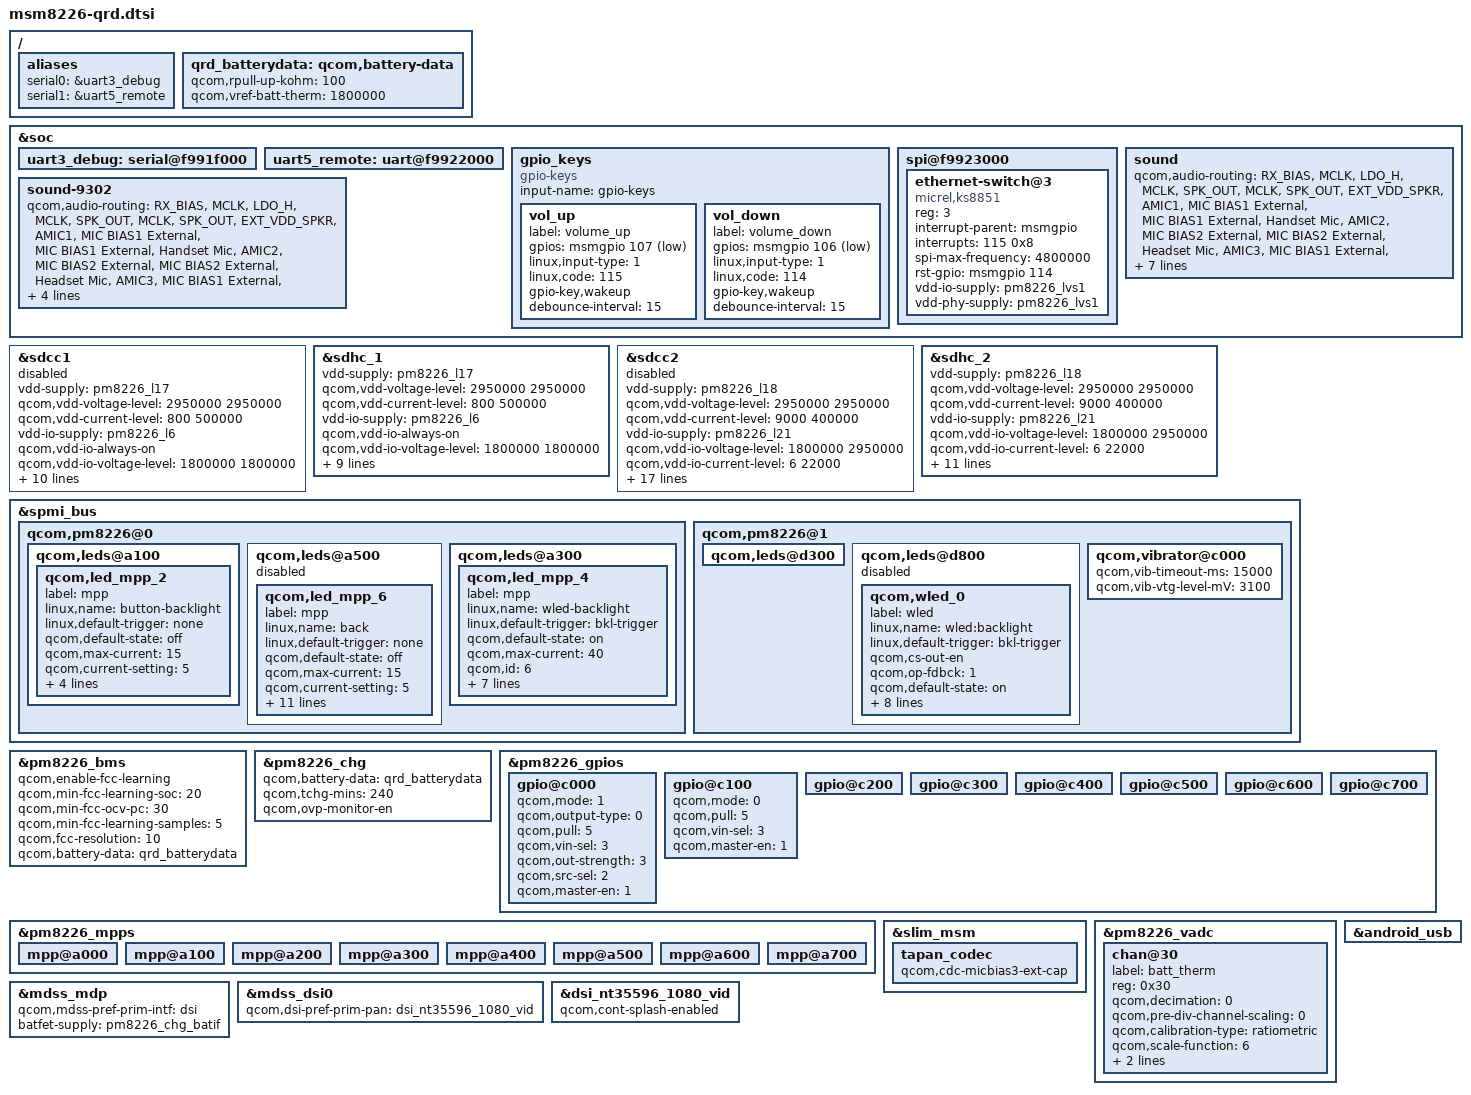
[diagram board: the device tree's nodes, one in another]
/* Copyright (c) 2013, The Linux Foundation. All rights reserved.
 *
 * This program is free software; you can redistribute it and/or modify
 * it under the terms of the GNU General Public License version 2 and
 * only version 2 as published by the Free Software Foundation.
 *
 * This program is distributed in the hope that it will be useful,
 * but WITHOUT ANY WARRANTY; without even the implied warranty of
 * MERCHANTABILITY or FITNESS FOR A PARTICULAR PURPOSE.  See the
 * GNU General Public License for more details.
 */

/include/ "msm8226-camera-sensor-qrd.dtsi"
/*qiang.zhang@Bas Drv add for remote control, uart5 config*/
/ {
    aliases {
        serial0 = &uart3_debug;
        serial1 = &uart5_remote;
    };
};
&soc {
	/*qiang.zhang@Bas Drv add for remote control, uart5 config*/
	uart3_debug: serial@f991f000 {
		status = "ok";
	};
	
	uart5_remote: uart@f9922000 {
		status = "ok";
	};	

	gpio_keys {
		compatible = "gpio-keys";
		input-name = "gpio-keys";
		
		/*Yixue.Ge@ProDrv.BL del for they are no be used at this project*/
		/*camera_focus {
			label = "camera_focus";
			gpios = <&msmgpio 108 0x1>;
			linux,input-type = <1>;
			linux,code = <0x210>;
			gpio-key,wakeup;
			debounce-interval = <15>;
		};

		camera_snapshot {
			label = "camera_snapshot";
			gpios = <&msmgpio 107 0x1>;
			linux,input-type = <1>;
			linux,code = <0x2fe>;
			gpio-key,wakeup;
			debounce-interval = <15>;
		};*/

		vol_up {
			label = "volume_up";
			gpios = <&msmgpio 107 0x1>;
			linux,input-type = <1>;
			linux,code = <115>;
			gpio-key,wakeup;
			debounce-interval = <15>;
		};
		
		vol_down { /*Yixue.Ge@ProDrv.BL add for volume down key*/
			label = "volume_down";
			gpios = <&msmgpio 106 0x1>;
			linux,input-type = <1>;
			linux,code = <114>;
			gpio-key,wakeup;
			debounce-interval = <15>;
		};
	};

	spi@f9923000 {
		ethernet-switch@3 {
			compatible = "micrel,ks8851";
			reg = <3>;
			interrupt-parent = <&msmgpio>;
			interrupts = <115 0x8>;
			spi-max-frequency = <4800000>;
			rst-gpio = <&msmgpio 114 0>;
			vdd-io-supply = <&pm8226_lvs1>;
			vdd-phy-supply = <&pm8226_lvs1>;
		};
	};

	sound {
		qcom,audio-routing =
			"RX_BIAS", "MCLK",
			"LDO_H", "MCLK",
			"SPK_OUT", "MCLK",
			"SPK_OUT", "EXT_VDD_SPKR",
			"AMIC1", "MIC BIAS1 External",
			"MIC BIAS1 External", "Handset Mic",
			"AMIC2", "MIC BIAS2 External",
			"MIC BIAS2 External", "Headset Mic",
			"AMIC3", "MIC BIAS1 External",
			"MIC BIAS1 External", "Analog Mic3",
			"AMIC4", "MIC BIAS3 External",
			"MIC BIAS3 External", "Analog Mic4";

		qcom,cdc-mclk-gpios = <&pm8226_gpios 1 0>;
		qcom,cdc-vdd-spkr-gpios = <&pm8226_gpios 2 0>;
		/*Wensheng.zha@Audio, 2014.03.21, add for 14013 speaker*/
		//qcom,cdc-us-euro-gpios = <&msmgpio 69 0>;
		qcom,cdc-enable-spk-gpios = <&msmgpio 62 0>;
		qcom,cdc-boost-spk-gpios = <&msmgpio 69 0>;		
	};

	sound-9302 {
		qcom,audio-routing =
			"RX_BIAS", "MCLK",
			"LDO_H", "MCLK",
			"SPK_OUT", "MCLK",
			"SPK_OUT", "EXT_VDD_SPKR",
			"AMIC1", "MIC BIAS1 External",
			"MIC BIAS1 External", "Handset Mic",
			"AMIC2", "MIC BIAS2 External",
			"MIC BIAS2 External", "Headset Mic",
			"AMIC3", "MIC BIAS1 External",
			"MIC BIAS1 External", "Handset Mic";

		qcom,cdc-mclk-gpios = <&pm8226_gpios 1 0>;
		qcom,cdc-vdd-spkr-gpios = <&pm8226_gpios 2 0>;
		qcom,cdc-us-euro-gpios = <&msmgpio 69 0>;
	};
};

&sdcc1 {
	vdd-supply = <&pm8226_l17>;
	qcom,vdd-voltage-level = <2950000 2950000>;
	qcom,vdd-current-level = <800 500000>;

	vdd-io-supply = <&pm8226_l6>;
	qcom,vdd-io-always-on;
	qcom,vdd-io-voltage-level = <1800000 1800000>;
	qcom,vdd-io-current-level = <250 154000>;

	qcom,pad-pull-on = <0x0 0x3 0x3>; /* no-pull, pull-up, pull-up */
	qcom,pad-pull-off = <0x0 0x3 0x3>; /* no-pull, pull-up, pull-up */
	qcom,pad-drv-on = <0x4 0x4 0x4>; /* 10mA, 10mA, 10mA */
	qcom,pad-drv-off = <0x0 0x0 0x0>; /* 2mA, 2mA, 2mA */

	qcom,clk-rates = <400000 25000000 50000000 100000000 200000000>;
	qcom,sup-voltages = <2950 2950>;

	qcom,bus-speed-mode = "HS200_1p8v", "DDR_1p8v";
	qcom,nonremovable;

	status = "disabled";
};

&sdhc_1 {
	vdd-supply = <&pm8226_l17>;
	qcom,vdd-voltage-level = <2950000 2950000>;
	qcom,vdd-current-level = <800 500000>;

	vdd-io-supply = <&pm8226_l6>;
	qcom,vdd-io-always-on;
	qcom,vdd-io-voltage-level = <1800000 1800000>;
	qcom,vdd-io-current-level = <250 154000>;

	qcom,pad-pull-on = <0x0 0x3 0x3>; /* no-pull, pull-up, pull-up */
	qcom,pad-pull-off = <0x0 0x3 0x3>; /* no-pull, pull-up, pull-up */
	qcom,pad-drv-on = <0x4 0x4 0x4>; /* 10mA, 10mA, 10mA */
	qcom,pad-drv-off = <0x0 0x0 0x0>; /* 2mA, 2mA, 2mA */

	qcom,clk-rates = <400000 25000000 50000000 100000000 200000000>;
	qcom,bus-speed-mode = "HS200_1p8v", "DDR_1p8v";
	qcom,nonremovable;

	status = "ok";
};

&sdcc2 {
	vdd-supply = <&pm8226_l18>;
	qcom,vdd-voltage-level = <2950000 2950000>;
	qcom,vdd-current-level = <9000 400000>;

	vdd-io-supply = <&pm8226_l21>;
	qcom,vdd-io-voltage-level = <1800000 2950000>;
	qcom,vdd-io-current-level = <6 22000>;

	qcom,pad-pull-on = <0x0 0x3 0x3>; /* no-pull, pull-up, pull-up */
	qcom,pad-pull-off = <0x0 0x3 0x3>; /* no-pull, pull-up, pull-up */
	qcom,pad-drv-on = <0x4 0x4 0x4>; /* 10mA, 10mA, 10mA */
	qcom,pad-drv-off = <0x0 0x0 0x0>; /* 2mA, 2mA, 2mA */

	qcom,clk-rates = <400000 25000000 50000000 100000000 200000000>;
	qcom,sup-voltages = <2950 2950>;

	qcom,xpc;
	qcom,bus-speed-mode = "SDR12", "SDR25", "SDR50", "DDR50", "SDR104";
	qcom,current-limit = <400>;

	#address-cells = <0>;
	interrupt-parent = <&sdcc2>;
	interrupts = <0 1 2>;
	#interrupt-cells = <1>;
	interrupt-map-mask = <0xffffffff>;
	interrupt-map = <0 &intc 0 125 0
			1 &intc 0 220 0
			2 &msmgpio 38 0x3>;
	interrupt-names = "core_irq", "bam_irq", "status_irq";
	cd-gpios = <&msmgpio 38 0x1>;

	status = "disabled";
};

&sdhc_2 {
	vdd-supply = <&pm8226_l18>;
	qcom,vdd-voltage-level = <2950000 2950000>;
	qcom,vdd-current-level = <9000 400000>;

	vdd-io-supply = <&pm8226_l21>;
	qcom,vdd-io-voltage-level = <1800000 2950000>;
	qcom,vdd-io-current-level = <6 22000>;

	qcom,pad-pull-on = <0x0 0x3 0x3>; /* no-pull, pull-up, pull-up */
	qcom,pad-pull-off = <0x0 0x3 0x3>; /* no-pull, pull-up, pull-up */
	qcom,pad-drv-on = <0x4 0x4 0x4>; /* 10mA, 10mA, 10mA */
	qcom,pad-drv-off = <0x0 0x0 0x0>; /* 2mA, 2mA, 2mA */

	qcom,clk-rates = <400000 25000000 50000000>;

	#address-cells = <0>;
	interrupt-parent = <&sdhc_2>;
	interrupts = <0 1 2>;
	#interrupt-cells = <1>;
	interrupt-map-mask = <0xffffffff>;
	interrupt-map = <0 &intc 0 125 0
			1 &intc 0 221 0
			2 &msmgpio 38 0x3>;
	interrupt-names = "hc_irq", "pwr_irq", "status_irq";
	cd-gpios = <&msmgpio 38 0x1>;

	status = "ok";
};

&spmi_bus {
	qcom,pm8226@0 {
		qcom,leds@a100 {
			status = "okay";
			qcom,led_mpp_2 {
				label = "mpp";
				linux,name = "button-backlight";
				linux,default-trigger = "none";
				qcom,default-state = "off";
				qcom,max-current = <15>;
				qcom,current-setting = <5>;
				qcom,id = <6>;
				qcom,mode = "manual";
				qcom,source-sel = <1>;
				qcom,mode-ctrl = <0x60>;
			};
		};



		qcom,leds@a500 {
			status = "disable";
			qcom,led_mpp_6 {
				label = "mpp";
				linux,name = "back";
                //#ifndef VENDOR_EDIT
                //Lycan.Wang@Prd.BasicDrv, 2014-02-26 Remove for no linux trigger
                //linux,default-trigger = "battery-charging";
                //#else
                linux,default-trigger = "none";
                //#endif /* VENDOR_EDIT */
				qcom,default-state = "off";
				qcom,max-current = <15>;
				qcom,current-setting = <5>;
				qcom,id = <6>;
				qcom,mode = "pwm";
				qcom,pwm-us = <1000>;
				qcom,mode-ctrl = <0x60>;
				qcom,source-sel = <10>;
				qcom,pwm-channel = <5>;
				qcom,start-idx = <1>;
                //#ifndef VENDOR_EDIT
                //Lycan.Wang@Prd.BasicDrv, 2014-02-28 Modify for breath-led blink para
                //qcom,ramp-step-ms = <120>;
                //qcom,duty-pcts = [00 00 00 00 00
                //		  00 00 00 00 00
                //		  50 00 00 00 00
                //		  00 00 00 00 00
                //		  00];
                //#else /* VENDOR_EDIT */
                qcom,ramp-step-ms = <100>;
				qcom,duty-pcts = [10 15 20 25 30 35 40 45 50
                          55 60 65 70 75 80 80 80 80 80
                          80 80 75 70 65 60 55 50 45 40
                          35 30 25 20 15 10 00 00 00 00
                          00 00 00 00 00 00 00 00 00 00
                          00 00 00 00 00 00];
                //#endif /* VENDOR_EDIT */
				qcom,use-blink;
			};
		};
	qcom,leds@a300 {
			status = "okay";
			qcom,led_mpp_4 {
				label = "mpp";
				linux,name = "wled-backlight";
				linux,default-trigger = "bkl-trigger";
				qcom,default-state = "on";
				qcom,max-current = <40>;
				qcom,id = <6>;
				qcom,source-sel = <8>;
				qcom,mode-ctrl = <0x10>;
				qcom,pwm-channel = <0>;
				qcom,pwm-us = <31>;
				qcom,vin-ctrl = <0x03>;
				qcom,mode = "pwm";
				qcom,min-brightness = <9>;
			};
		};
		
	};

	qcom,pm8226@1 {	
		qcom,leds@d300 {
				status = "okay"; //zhengrong.zhang@camera.drv modify for led from tong.han modify
		};

		qcom,leds@d800 {
//caven.han@basic.drv added avoid loading devices doesn't exist for 13095
//#ifdef VENDOR_EDIT
				status = "disable";
//#else
//				status = "okay";
//#endif
			qcom,wled_0 {
				label = "wled";
				linux,name = "wled:backlight";
				linux,default-trigger = "bkl-trigger";
				qcom,cs-out-en;
				qcom,op-fdbck = <1>;
				qcom,default-state = "on";
				qcom,max-current = <20>;
				qcom,ctrl-delay-us = <0>;
				qcom,boost-curr-lim = <3>;
				qcom,cp-sel = <0>;
				qcom,switch-freq = <11>;
				qcom,ovp-val = <0>;
				qcom,num-strings = <1>;
				qcom,id = <0>;
			};
		};
		
		qcom,vibrator@c000 {
			status = "okay";
			qcom,vib-timeout-ms = <15000>;
			qcom,vib-vtg-level-mV = <3100>;
		};

	};
};

/ {
	qrd_batterydata: qcom,battery-data {
		qcom,rpull-up-kohm = <100>;
		qcom,vref-batt-therm = <1800000>;

		/include/ "batterydata-qrd-4v35-2000mah.dtsi"
	};
};

&pm8226_bms {
	status = "okay";
	qcom,enable-fcc-learning;
	qcom,min-fcc-learning-soc = <20>;
	qcom,min-fcc-ocv-pc = <30>;
	qcom,min-fcc-learning-samples = <5>;
	qcom,fcc-resolution = <10>;
	qcom,battery-data = <&qrd_batterydata>;
};

&pm8226_chg {
	status = "okay";
	qcom,battery-data = <&qrd_batterydata>;
	qcom,tchg-mins = <240>;
	qcom,ovp-monitor-en;
};

&pm8226_gpios {
	gpio@c000 { /* GPIO 1 */
		/* XO_PMIC_CDC_MCLK enable for tapan codec */
		qcom,mode = <1>;		/* Digital output */
		qcom,output-type = <0>;	/* CMOS logic */
		qcom,pull = <5>;		/* QPNP_PIN_PULL_NO*/
		qcom,vin-sel = <3>;		/* QPNP_PIN_VIN3 */
		qcom,out-strength = <3>;/* QPNP_PIN_OUT_STRENGTH_HIGH */
		qcom,src-sel = <2>;		/* QPNP_PIN_SEL_FUNC_1 */
		qcom,master-en = <1>;	/* Enable GPIO */
	};

	gpio@c100 { /* GPIO 2 */
		qcom,mode = <0>;
		qcom,pull = <5>;
		qcom,vin-sel = <3>;
		qcom,master-en = <1>;
	};

	gpio@c200 { /* GPIO 3 */
	};

	gpio@c300 { /* GPIO 4 */
	};

	gpio@c400 { /* GPIO 5 */
	};

	gpio@c500 { /* GPIO 6 */
	};

	gpio@c600 { /* GPIO 7 */
	};

	gpio@c700 { /* GPIO 8 */
	};
};

&pm8226_mpps {
	mpp@a000 { /* MPP 1 */
	};

	mpp@a100 { /* MPP 2 */
	};

	mpp@a200 { /* MPP 3 */
	};

	mpp@a300 { /* MPP 4 */
	};

	mpp@a400 { /* MPP 5 */
	};

	mpp@a500 { /* MPP 6 */
	};

	mpp@a600 { /* MPP 7 */
	};

	mpp@a700 { /* MPP 8 */
	};
};

&slim_msm {
	tapan_codec {
//#ifndef VENDOR_EDIT
// xiaojun.lv commented for mic bias use internal cap on 2014-2-20
//		qcom,cdc-micbias1-ext-cap;
//#endif
		qcom,cdc-micbias3-ext-cap;
	};
};

&pm8226_vadc {
	chan@30 {
		label = "batt_therm";
		reg = <0x30>;
		qcom,decimation = <0>;
		qcom,pre-div-channel-scaling = <0>;
		qcom,calibration-type = "ratiometric";
		qcom,scale-function = <6>;
		qcom,hw-settle-time = <2>;
		qcom,fast-avg-setup = <0>;
	};
};

&android_usb {
//#ifndef VENDOR_EDIT
//Lycan.Wang@Prd.BasicDrv, 2014-01-26 Remove for USB config
//	qcom,android-usb-cdrom;
//	qcom,android-usb-internal-ums;
//#endif /* VENDOR_EDIT */
};

&mdss_mdp {
	qcom,mdss-pref-prim-intf = "dsi";
	batfet-supply = <&pm8226_chg_batif>;
};

&mdss_dsi0 {
	qcom,dsi-pref-prim-pan = <&dsi_nt35596_1080_vid>;
};

&dsi_nt35596_1080_vid {
	qcom,cont-splash-enabled;
};
